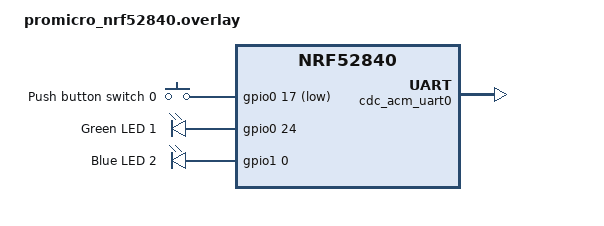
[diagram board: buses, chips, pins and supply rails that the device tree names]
/*
 * Copyright (c) 2021 Nordic Semiconductor ASA
 *
 * SPDX-License-Identifier: LicenseRef-Nordic-5-Clause
 */

/ {
	chosen {
		zephyr,console = &cdc_acm_uart0;
	};

	buttons {
		compatible = "gpio-keys";

		button0: button_0 {
			gpios = <&gpio0 17 (GPIO_PULL_UP | GPIO_ACTIVE_LOW)>;
			label = "Push button switch 0";
		};
	};

	leds {
		led1: led_1 {
			gpios = <&gpio0 24 GPIO_ACTIVE_HIGH>;
			label = "Green LED 1";
		};
		led2: led_2 {
			gpios = <&gpio1 0 GPIO_ACTIVE_HIGH>;
			label = "Blue LED 2";
		};
	};

};

&zephyr_udc0 {
	cdc_acm_uart0: cdc_acm_uart0 {
		compatible = "zephyr,cdc-acm-uart";
	};
};

